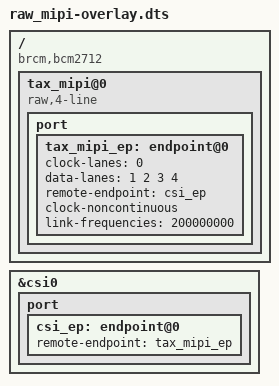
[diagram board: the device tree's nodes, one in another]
/dts-v1/;
/plugin/;

/ {
    compatible = "brcm,bcm2712";

    csi_frag: fragment@0 {
        target = <&csi0>;
        csi: __overlay__ {
            status = "okay";
            port {
                csi_ep: endpoint@0 {
                    remote-endpoint = <&tax_mipi_ep>;
                };
            };
        };
    };

    fragment@1 {
        target-path = "/";
        __overlay__ {
            tax_mipi@0 {
                compatible = "raw,4-line";
                #address-cells = <0x01>;
                #size-cells = <0x00>;

                status = "okay";

                port {
                    tax_mipi_ep: endpoint@0 {
                        clock-lanes = <0>;
                        data-lanes = <1 2 3 4>;
                        remote-endpoint = <&csi_ep>;
                        clock-noncontinuous;
                        link-frequencies =
                            /bits/ 64 <200000000>;
                    };
                };
            };
        };
    };
};
